# DA1470x register map
Vendor: Dialog; Series: DA1470x; File version: 1.2
CPU: CM33 r0p2, little endian, MPU, FPU, DSP, VTOR, 4 interrupt priority bits
Registers are 32-bit, read-write, reset 0x0 unless marked. A register's access mark holds for its fields unless they carry their own. Offsets are from the block's base; [hi:lo] are bit positions.

## CHARGER (part 1 of 2) — CHARGER registers
Base 0x51000600
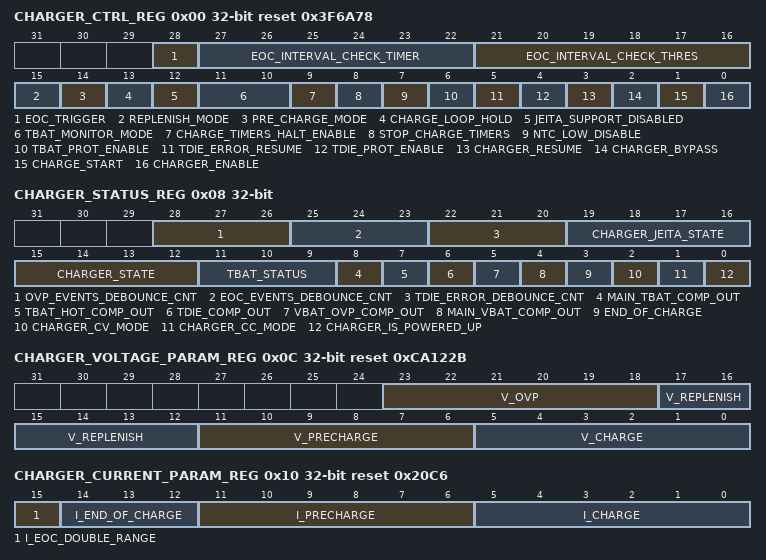
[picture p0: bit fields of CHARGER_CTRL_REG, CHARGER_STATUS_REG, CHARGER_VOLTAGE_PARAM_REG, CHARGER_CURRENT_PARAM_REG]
0x00 CHARGER_CTRL_REG reset 0x3F6A78 — Charger main control register
  [28] EOC_TRIGGER — 0 = Edge-sensitive End-of-Charge detection support is enabled (default). The Charger's digital block expects a positive edge of the End-of-Charge signal coming from the Charger's analog circuit to let the respective debounce counters start and enable the FSM switch to the END_OF_CHARGE state, if the signal is stable. 1 = Level-sensitive End-of-Charge detection is enabled. In this mode, the Charger's digital block only monitors the level of the End-of-Charge signal coming from the analog circuit and if this is seen high in either CC_CHARGE or CV_CHARGE state, the EOC debounce counters start.
  [27:22] EOC_INTERVAL_CHECK_TIMER ro — The specific bit-field determines the current state of the timer used to periodically check the End-of-Charge signal, as soon as the Charger's FSM is either in CC_CHARGE or CV_CHARGE state. Thus, as soon as the Charger's FSM enters the CC_CHARGE state: - The timer starts increasing when a positive edge detection on End-of-Charge signal occurs. - It keeps increasing until reaching the programmed EOC_INTERVAL_CHECK_THRES value, if and only if there is no detection of a negative edge on End-of-Charge signal. If this happens, the timer resets and starts over with a new End-of-Charge positive edge. - The timer also resets after having reached its programmed threshold or when the Charger's FSM next state is END_OF_CHARGE. This happens only after having found End-of-Charge signal asserted for 4 consecutive checks and provided that the specific signal has not de-asserted during the timer's interval. Note: It must be noted that out of these two states, the specific timer is kept to zero. It is also noted that this timer runs at the 1Mhz clock of the Charger's block and its value always ranges from 0 to the EOC_INTERVAL_CHECK_THRES value set in the respective bit-field of CHARGER_CTRL_REG.
  [21:16] EOC_INTERVAL_CHECK_THRES — This bit-field determines the periodic interval of checking the End-of-Charge signal, when the Charger's FSM is either in CC_CHARGE or in CV_CHARGE state. To implement this, a dedicated timer has been used, counting from zero up to the value programmed into this bit-field (see also EOC_INTERVAL_CHECK_TIMER field's description). As soon as this timer reaches the programmed value, the End-of-Charge signal is sampled and depending on its status (high or low), another counter, keeping the number of consecutive End-of-Charge events, is increased or not. See also the description of the EOC_DEBOUNCE_CNT bit-field of CHARGER_STATUS_REG, for this counter. Note: The specific bit-field should always be programmed to a non-zero value.
  [15] REPLENISH_MODE — When this bit-field is set and the Charger's FSM is in the BYPASSED state (thus, in Bypass mode), the internal multiplexer inside the digital part of the charger selects the Replenish, instead of the Pre-charge setting to be driven to the main Vbat comparator of the Charger's analogue circuitry. By this way, SW can read the respective analogue comparator's output in CHARGER_STATUS_REG (bit-field MAIN_VBAT_COMP_OUT), after the battery's volrtage has reached the End-of-Charge level, and determine if the battery voltage has dropped below the Replenish level, re-starting the battery charging accordingly. Note: When the Charger's FSM is active and operational, this bit-field is don't care and the FSM determines which level (Pre-charge or Replenish) will be selected and driven to the analogue, depending on the current state. It is also noted that the supported Pre-charge and Replenish levels can be viewed in the respective bit-fields defined in CHARGER_VOLTAGE_PARAM_REG register.
  [14] PRE_CHARGE_MODE — When set, this bit-field enables a signal of the same name with the bit-field, driven from the Charger's digital part towards the analogue circuitry, in order to determine the current in Pre-Charge mode. If the Charger's FSM is active and operational, the specific bit-field is don't care. Hence, it is considered only when the Charger's FSM has reached the BYPASSED state (thus, in Bypass mode). With the Charger's FSM being bypassed, SW should take over control and set the specific bit-field, in order to deliver the Pre-Charge instead of the normal Charge current to the Charger's analogue circuitry, during the Pre-Charge phase. Note: See also the description of CHARGER_CURRENT_PARAM_REG register for the Pre-Charge and normal Charge current levels supported.
  [13] CHARGE_LOOP_HOLD — When set, this bit-field disables charging, provided that the Charger's FSM has switched to the BYPASSED state. This is possible only by setting the CHARGER_BYPASS bit-field of this register. Thus, as soon as the Charger's FSM is bypassed, the respective signal driven by the FSM is overruled by this bit-field, making the analogue part of the Charger controllable also in this mode. If the Charger's FSM is not bypassed, this bit-field is don't care.
  [12] JEITA_SUPPORT_DISABLED — 0 = Charger's JEITA FSM monitoring the battery temperature checks also if battery temperature is in the Warm or Cool zones. In that case, it updates accordingly all the Charger's voltage levels (Charge, Pre-Charge, Replenish and OVP) programmed in CHARGER_VOLTAGE_PARAM_REG, as well as the charge and pre-charge current settings of CHARGER_CURRENT_PARAM_REG, depending on the temperature zone determined by the analogue circuitry of the Charger (see also the JEITA registers of the Charger's register file for the Voltage/Current levels in Warm and Cool temperature zones). 1 = Charger's JEITA FSM monitoring the battery temperature checks only if battery temperature is either in the Hot or Cold zones. In that case, it notifies the main Charger FSM to stop charging automatically, when in Hot zone. The same will happen also for the case of Cold, unless the NTC_LOW_DISABLE bit-field of CHARGER_CTRL_REG is set. Note : It is not recommended to have the specific bit-field kept to '0' (and thus the JEITA support enabled), if at the same time the bit-field TBAT_PROT_ENABLE of the same register is also '0'. Thus, JEITA support should be coupled with the Battery's temperature protection.
  [11:10] TBAT_MONITOR_MODE — Battery temperature pack monitoring modes, according to the following encoding: 00 = Battery temperature state checked and updated once, as soon as the charger is powered-up and settled. 01 = Battery temperature state checked periodically, depeding on TBAT_MON_TIMER_REG.TBAT_MON_INTERVAL and provided that Charger has been powered-up and charger's FSM is enabled. 10 = Battery temperature state checked periodically depending on TBAT_MON_TIMER_REG.TBAT_MON_INTERVAL, provided that Charger is powered-up and regardless if the Charger's FSM is enabled or not. Hence, this mode can be effective regardless of the state of CHARGE_START bit-field of CHARGER_CTRL_REG. 11 = When selected, it freezes the Battery temperature monitor FSM, as soon as the latter reaches the CHECK_IDLE state (see also CHARGER_STATUS_REG.CHARGER_JEITA_STATE bit-field's description for the states of this FSM). In this mode, the monitoring of Battery temperature is possible only by checking the status of TBAT_HOT_COMP_OUT and MAIN_TBAT_COMP_OUT bit-fields of CHARGER_STATUS_REG, thus by letting SW take over monitoring. This setting may be used in conjunction with Bypass mode (by setting CHARGER_BYPASS of CHARGER_CTRL_REG), so that both charging and battery temperature status monitoring are controlled by SW.
  [9] CHARGE_TIMERS_HALT_ENABLE — 0 = Charge timeout timers continue running when charging is disabled because of a Die or of a Battery temperature error, if and only if STOP_CHARGE_TIMERS bit-field is '0' (default). If it is '1', the counters are stopped also in TDIE_PROT and TBAT_PROT states. 1 = Charge timeout timers are halted in case of a Die or of a Battery temperature error. In that case, the global charge timer is stopped as soon as the Charger's FSM moves to TDIE_PROT or TBAT_PROT state. Also, either the Pre-Charge, the CC_CHARGE or the CV_CHARGE timer is also stopped, depending on the charging state of the FSM when the Die/Battery temperature error has been detected.
  [8] STOP_CHARGE_TIMERS — 0 = Charger's Pre-Charge, CC, CV and Total charge timeout timers are ticking properly, running at the 1Hz clock. 1 = All four Charger's timeout timers are halted, counting is disabled. The counters will be reset when the FSM is either in DISABLED or in END_OF_CHARGE state. Note: Value '0' is the recommended, '1' is a test mode, since it will globally halt the four timers and thus will block the generation of the respective timer expiration IRQs.
  [7] NTC_LOW_DISABLE — 0 = Charging is disabled when the battery temperature is found to have reached the "COLD" region. Therefore, the Charger's FSM moves directly to "TBAT_PROT" error and generates an IRQ to notify the system accordingly, in case the respective IRQ mask bit of CHARGER_ERROR_IRQ_MASK_REG is set. Also, CHARGER_ERROR_IRQ_STATUS_REG. TBAT_ERROR_IRQ field is updated accordingly. 1 = Charging is allowed to continue, even when the battery temperature pack reaches the "COLD" region. Consequently, the FSM continues charging and no battery temperature error event is generated.
  [6] TBAT_PROT_ENABLE — 0 = Battery temperature protection disabled 1 = Battery temperature protection enabled. Charging will be stopped in case Battery temperature reaches "Hot" zone. It will also be disabled when reaching "Cold" zone, provided that CHARGER_CTRL_REG.NTC_LOW_DISABLE is not set. This is handled by the Charger's FSM, which moves directly to the respective error state (TBAT_PROT), also generating an Error IRQ if the respective IRQ mask bit is set (see also CHARGER_ERROR_IRQ_MASK_REG).
  [5] TDIE_ERROR_RESUME — 0 = FSM will not resume from a Die temperature error. Consequently, its state will be staying to "TDIE_PROT", for as long as this bit-field is kept low, regardless of the status of the die tempeture comparator. Also, disabling the specific bit-field will reset the Die temperature error debounce counter, when the Charger's FSM is in TDIE_PROT state (so when a Die temperature error has been already detected) and the specific counter will remain frozen to 0 until the TDIE_ERROR_RESUME bit-field is set (see also the TDIE_ERROR_DEBOUNCE_CNT bit-field of CHARGER_STATUS_REG). 1 = FSM will resume from a Die temperature error, as soon as the respective analogue compator confirms that die temperature is again below the maximum allowed level. It is noted that the maximum Die temperature level is programmable via the CHARGER_TEMPSET_PARAM_REG register's respective bit-field (T_DIE_MAX).
  [4] TDIE_PROT_ENABLE — 0 = Die temperature protection is disabled, thus charging will not be disabled by the Charger's FSM in case of a Die temperature error. 1 = Die temperature protection is enabled, thus the Charger's FSM will move to "TDIE_PROT" state, disabling charging at the same time. It is noted that the Die temperature error event will be logged in the respective status bit of CHARGER_IRQ_ERROR_STATUS_REG and an IRQ will be generated, if and only if the corresponding mask bit of CHARGER_IRQ_MASK_REG is set.
  [3] CHARGER_RESUME — 0 = Charger's FSM is not enable to resume from a charge timeout error or a Vbat OVP (Over-Voltage Protection) error. Consequently, FSM stays in "ERROR" state. 1 = Charger's FSM will resume from a charge timeout or from an OVP error, thus its state will move from "ERROR" to "DISABLED" state, so that the charge cycle starts-over. It is noted that in the case of a Vbat OVP error, the FSM will leave "ERROR" state, as soon as the Vbat comparator for the OVP level shows that Vbat is again OK (so lower than the OVP setting).
  [2] CHARGER_BYPASS — 0 = Charger's FSM is active and running, notifying SW upon switching between its states 1 = Charger's FSM is bypassed, so its state stays to "BYPASS", so SW should take over the monitoring of the battery voltage and control of the charger.
  [1] CHARGE_START — 0 = Charger's FSM is disabled, FSM stays at "DISABLED" state 1 = Charger's FSM is enabled, so FSM's state can move from DISABLED to the actual charge states, starting from "PRE_CHARGE".
  [0] CHARGER_ENABLE — 0 = Charger's analogue circuitry is powered-down 1 = Charger's analogue circuitry is being powered-up and will be available after a certain settling time (in ms). As soon as this bit-field is set, the Charger's FSM waits for this settling time, before proceeding into DISABLED state, where it checks the Vbat level, as well as the Die temperature and the Battery temperature states. This is mandatory, before the actual charging begins, so before the FSM moves to PRE_CHARGE state. It is finally noted that the settling time is configurable via CHARGER_PWR_UP_TIMER_REG, counting with the 1Khz clock. Note: The Charger clocks must have been enabled first, by setting the CLK_SYS_REG[CLK_CHG_EN] bit-field to '1', in order to let the FSM proceed.
0x08 CHARGER_STATUS_REG — Charger main status register
  [28:26] OVP_EVENTS_DEBOUNCE_CNT ro — The specific bit-field returns the consecutive number of times Vbat has exceeded the programmed Over-Voltage Protection (OVP) level. It is used to determine when the Charger's FSM will exit any of the charging states (PRE/CC/CV_CHARGE) and will switch to the ERROR state due to an OVP error. This will happen as soon as the respective counter of OVP events reaches or exceeds a fixed number (4), similar to the approach adopted in the End-of-Charge and Die Temperature debouncing mechanisms. The specific counter increases only while the Charger's FSM is in any of the three charging,states, the Vbat OVP interval check timer has reached the threshold set and when Vbat OVP comparator's output is asserted. Note 1 : By default, as soon as the counter reaches 4, the FSM will switch to the ERROR state and the counter will reset again. Thus, in that case the specific counter ranges from 0 to 4 and vice-versa. However, if the monitoring of Vbat OVP comparator's state is less frequent than 5 (4+1) times the CHARGER_OVP_COMP_TIMER_REG[OVP_INTERVAL_CHECK_THRES] and Vbat has exceeded the OVP voltage level based on the comparator's output signal, then this counter will exceed 4 and may overflow. This will not harm, however, the detection of the OVP event, as it only increases the number of OVP event occurrences by the debounce timer, until the OVP comparator timer's settling time has expired. Thus, the Charger FSM will again switch to ERROR when the counter has reached or exceeded 4 (bit [2] of OVP_EVENTS_DEBOUNCE_CNT is set) and the OVP comparator's timer has expired. Note 2: See also the OVP_INTERVAL_CHECK_TIMER, OVP_INTERVAL_CHECK_THRES of CHARGER_OVP_COMP_TIMER_REG, for the debouncing mechanism of the Vbat OVP comparator's output.
  [25:23] EOC_EVENTS_DEBOUNCE_CNT ro — The specific bit-field returns the number of times the End-of-Charge signal has been consecutively found to be high. It is used to determine when the Charger's FSM will switch from CV_CHARGE to END_OF_CHARGE state, implementing a debounce mechanism on End-of-Charge signal, coming from the analogue circuitry of the Charger towards the FSM. The specific counter, running with the Charger's 1Mhz clock: - Increases after detecting that the End-of-Charge signal is high when the respective interval for the End-of-Charge check expires. This actually happens after having detected either a positive edge on the End-of-Charge signal or after having seen the signal's level to be high (see also CHARGER_CTRL_REG[EOC_TRIGGER]) , since only after that is it possible for the interval timer to start ticking. - Resets to zero when End-of-Charge is seen low when the interval timer has expired or when an End-of-Charge negative edge is seen before the timer's expiration, starting-over. - Does not count if End-of-Charge signal is seen high and either the CV_MODE signal (also driven by the analogue circutry) or the End-of-Charge signal of the previous clock cycle is seen low. - Is reset when the Charger's FSM is not in either the CC_CHARGE or the CV_CHARGE state or after having reached "100"(4). This is the threshold after which the End-of-Charge signal is considered stable by the Charger's FSM, to switch to the END_OF_CHARGE state. Thus, in practice, the specific counter (and bit-field) ranges between 0 and 4. Note: See also the EOC_INTERVAL_CHECK_TIMER/THRES bit-fields of CHARGER_CTRL_REG.
  [22:20] TDIE_ERROR_DEBOUNCE_CNT ro — The specific bit-field returns the consecutive number of times the Die temperature is seen either above (for the case of an error) or below (for the case of recovering from an error) the set Die temperature level.This is performed by a counter, which is increased: - Each time the Die temperature comparator shows that Die temperature exceeds the set level, and while charging is active, provided that Die temperature protection is enabled. If, however, the CHARGER_CTRL_REG.TDIE_PROT_ENABLE bit-field is not set, the counter is reset and stays frozen to zero. - Each time the Die temperature comparator shows that Die temperature is again below the set level, and while the FSM is in the Die temperature protection error state (TDIE_PROT) and the TDIE_ERROR_RESUME bit-field of CHARGER_CTRL_REG is set. If the specific bit-field is not set, the debounce counter is reset to 0 and it is kept frozen until the FSM is again enabled to resume from Die temperature errors. If the Die temperature comparator of the Charger's analogue circuitry shows that temperature has exceeded the programmed level for four consecutive times and charging is active, the Charger's FSM considers this as a Die temperature error and moves to the TDIE_PROT state, resetting the timer at the same time and of course halting charging. To recover from this state and resume charging, the FSM needs to see that Die temperature is below the programmed level for four consecutive times, again, provided that the TDIE_ERROR_RESUME bit-field of CHARGER_CTRL_REG is set. As soon as this happens, the error counter is again reset and the Charger's FSM resumes, by moving to PRE_CHARGE state. Consequently, the counter's value always ranges from 0 to 4. Note: When the Charger's FSM is in BYPASSED state, then this bit-field is reset and kept frozen to zero. Consequently, the number of times Die temperature has exceeded the pre-programmed threshold should be determined by SW.
  [19:16] CHARGER_JEITA_STATE ro — Returns the state of the Charger's JEITA FSM. This FSM is used to update the state of the battery temperature pack, depending on the value programmed in CHARGER_CTRL_REG.TBAT_MONITOR_MODE bit-field. The encoding of the states is as follows: 0x0 = CHECK_IDLE 0x1 = CHECK_THOT 0x2 = CHECK_TCOLD 0x3 = CHECK_TWARMER 0x4 = CHECK_TWARM 0x5 = CHECK_TCOOLER 0x6 = CHECK_TCOOL 0x7 = CHECK_TNORMAL 0x8 = UPDATE_TBAT The FSM initially is in CHECK_IDLE state and starts checking the battery's temperature by visiting the states that check for the respective temperature area (Hot, Cold, Warmer, Warm, Cooler, Cool, Normal), in this order. If the battery temperature is found to be in one of the aforementioned zones, it directly moves to UPDATE_TBAT state, to update the battery temperature's state and notify the main FSM of the Charger about the battery temperature status, before returning to the CHECK_IDLE state. A Charger State IRQ will also be generated upon refreshing the battery temperature status (see also the description of CHARGER_STATE_IRQ_MASK_REG register). Note: It is also noted that if the battery temperature is not found to be in any of the Hot, Cold, Warmer, Warm, Cooler or Cool zones, the FSM concludes that it is in the Normal zone, so between Warm and Cool. Consequently, the state CHECK_TNORMAL lasts only one (1MHz) clock cycle and is used to properly update the Battery temperature status (TBAT_STATUS) accordingly, before the last state (UPDATE_TBAT) is visited.
  [15:12] CHARGER_STATE ro — Indicating the state of the Charger's main FSM, based on the following encoding: 0x0 = POWER_UP (Charger's power-up not yet set) 0x1 = INIT (Charger is being power-up, FSM waiting for the analogue to settle) 0x2 = DISABLED (Charger powered-up but charging not yet started) 0x3 = PRE_CHARGE (Pre-Charge state) 0x4 = CC_CHARGE (Constant Current state) 0x5 = CV_CHARGE (Constant Voltage state) 0x6 = END_OF_CHARGE (End-of-Charge state) 0x7 = TDIE_PROT (Die temperature protection state, visited when Die temperature limit is exceeded) 0x8 = TBAT_PROT (Battery temperature protection state, visited when Battery temperature is either COLD or HOT) 0x9 = BYPASSED (Bypassed state, visited only when the FSM is bypassed and SW takes over control) 0xA = ERROR (Error state, visited when a charge time-out occurs or in the case of Vbat exceeding over-voltage level)
  [11:9] TBAT_STATUS ro — Battery pack temperature status, according to the following encoding: 0x0 : Battery temperature in COLD zone (default) 0x1 : Battery temperature in COOLER zone (above COLD) 0x2 : Battery temperature in COOL zone (above COOLER) 0x3 : Battery temperature in NORMAL zone (above COOL and below WARM zones) 0x4 : Battery temperature in WARM zone (above NORMAL) 0x5 : Battery temperature in WARMER zone (above WARM and below HOT) 0x6 : Battery temperature in HOT zone It is noted that, according to the JEITA standard (supported if the JEITA_SUPPORT_DISABLED bit-field of CHARGER_CTRL_REG is not set), if the battery pack temperature is in the "HOT" zone, charging will always be stopped. The same will happen also for the case of the COLD zone, unless the "NTC_LOW_DISABLE" bit-field of CHARGER_CTRL_REG is set. In that case, charging will be continued.
  [8] MAIN_TBAT_COMP_OUT ro — Returns the status of the main battery temperature comparator. This comparator by default checks if the battery temperature is in the Cold zone. However, if JEITA support is enabled and battery temperature is found to not be in either the Hot or the Cold zone, the same comparator is used to check for the Warm and Cool zones, as JEITA suggests. The specific bit-field is suggested to be used in bypass mode and when the JEITA support is disabled (so when the battery temperature is checked agains the Hot and the Cold zones). In that case, the comparator checks the battery temperature agains the Cold level and its status can be as follows: 0 = Battery temperature pack is found to be below the Cold level, so in the non-allowed Cold temperature zone. Thus, charging will be disabled, provided that the NTC_LOW_DISABLE bit-field of CHARGER_CTRL_REG is not set. 1 = Battery temperature pack is found to be above the non-allowed Cold temperature zone. Thus, charging will be continued, provided that battery temperature will not be in the Hot zone as well. When the Charger's main FSM is active and JEITA is enabled, the Charger's digital block takes over and controls the respective comparator's output.
  [7] TBAT_HOT_COMP_OUT ro — Returns the status of the battery temperature comparator dedicated to the Hot temperature zone. 0 = Battery temperature pack is found to be below the Hot zone 1 = Battery temperature pack is found to be in the non-allowed Hot temperature zone. Thus, charging will be disabled, provided that battery temperature protection is enabled.
  [6] TDIE_COMP_OUT ro — 0 = Die temperature is found to be below the programmed level, set in CHARGER_TEMPSET_PARAM_REG.TDIE_SET level (normal operation) 1 = Die temperature is found to be above the set level. Charging will be disabled if Die temperature protection is enabled and the Die temperature is found to be above the set level four consecutive times (see also TDIE_ERROR_DEBOUNCE_CNT bit-field). In that case, the Charger's FSM will also move the respective error state (TDIE_PROT) and an IRQ may be generated, if the respective mask bit of CHARGER_ERROR_IRQ_MASK_REG is set.
  [5] VBAT_OVP_COMP_OUT ro — 0 = Vbat has not exceeded the Over-Voltage Protection (OVP) voltage limit, according to the respective analogue comparator's output. 1 = Vbat is found to have exceeded the OVP voltage setting, thus charging should be disabled. The OVP voltage settings are defined in CHARGER_VOLTAGE_PARAM_REG.V_OVP (for the Normal battery temperature zone), as well as in CHARGER_JEITA_V_OVP_REG (for Cool and Warm temperature zones, to comply with JEITA).
  [4] MAIN_VBAT_COMP_OUT ro — This bit-field reflects the status of the main Vbat comparator residing in the analogue circuitry of the Charger. This comparator is used to check Vbat against either the Pre-Charge or the Replenish voltage level, depending on what is driven by the Charger's digital block. Thus, when the FSM is active, the comparator gets as reference the Replenish setting as soon as the FSM has reached the END_OF_CHARGE state. Otherwise,the Pre-Charge voltage setting is driven, including the Bypass mode. According to the above, the encoding is as follows for the case the comparator compares Vbat against the Pre-Charge level: 0 = Vbat has not exceeded the set Pre-Charge voltage level. 1 = Vbat has reached or exceeded the set Pre-Charge voltage level. For the case the comparator compares agains the Replenish level (when the FSM has reached the END_OF_CHARGE state, so when the charging has been completed), the encoding is as follows: 0 = Vbat has dropped below the set Replenish level, so charging will re-start and the FSM will move to the PRE_CHARGE state. 1 = Vbat is still greater or equal to the set Replenish level, thus charging remains in hold and the FSM in END_OF_CHARGE state.
  [3] END_OF_CHARGE ro — 0 = Actual charge current is above the current level programmed in I_END_OF_CHARGE field of CHARGER_CURRENT_PARAM_REG (or charger is off) 1 = Actual charge current is below the current level programmed in I_END_OF_CHARGE bit-field of CHARGER_CURRENT_PARAM_REG.
  [2] CHARGER_CV_MODE ro — 0 = Charger's voltage loop not in regulation (or Charger is off) 1 = Charger's Constant Voltage (CV) mode active, voltage loop in regulation
  [1] CHARGER_CC_MODE ro — 0 = Charger's Current loop not in regulation (or Charger is off) 1 = Charger's Constant Current (CC) mode active, current loop in regulation
  [0] CHARGER_IS_POWERED_UP ro — 0 = Charger is either off or it is being powered-on but the analogue ciruitry is not yet settled. The charger's main FSM is either in POWER_UP or INIT states. 1 = Charger is powered-up, so its analogue ciruitry should now be settled. The Charger's FSM has left both power-up states (POWER_UP, INIT), so charging can start.
0x0C CHARGER_VOLTAGE_PARAM_REG reset 0xCA122B — Charger voltage settings register
  [23:18] V_OVP — This bit-field determines the VBAT Over-voltage protection limit. This Over-voltage protection level is used by the Charger's analogue circuitry and specifically by a dedicated comparator, the output of which is sampled by the digital block of the Charger. As soon as VBAT is detected to have reached or exceeded this level, the Charger's FSM moves to ERROR state, interrupting charging. If the respective Error IRQ mask bit is set, an Error IRQ pulse will be also generated. Regarding the actual range of supported values for this bit-field, see the the description of V_CHARGE bit-field of this register.
  [17:12] V_REPLENISH — This bit-field determines the absolute value (in V) of the Replenish voltage threshold. As soon as charging has been completed and the Charger's FSM has reached the END_OF_CHARGE state, the respective analogue comparator of the Charger compares VBAT with the Replenish level. If VBAT is found to have dropped below this level, charging should start-over again and in that case, the FSM moves again to the PRE_CHARGE state. Regarding the supported Replenish voltage levels, see the description of V_CHARGE bit-field.
  [11:6] V_PRECHARGE — This bit-field determines the voltage level at which the battery is considered as Pre-charged and therefore the Charger's FSM should move to the CC_CHARGE state, entering the Constant Current charging phase. Regarding the supported Pre-Charge voltage levels, see also the description of V_CHARGE bit-field of this register.
  [5:0] V_CHARGE — This bit-field determines the charge voltage levels supported. The supported levels are determined according to the following encoding: 0 : 2.80V 1 : 2.85V 2 : 2.90V 3 : 2.95V 4 : 3.00V 5 : 3.05V 6 : 3.10V 7 : 3.15V 8 : 3.20V 9 : 3.25V 10 : 3.30V 11 : 3.35V 12 : 3.40V 13 : 3.45V 14 : 3.50V 15 : 3.55V 16 : 3.60V 17 : 3.65V 18 : 3.70V 19 : 3.75V 20 : 3.80V 21 : 3.82V 22 : 3.84V 23 : 3.86V 24 : 3.88V 25 : 3.90V 26 : 3.92V 27 : 3.94V 28 : 3.96V 29 : 3.98V 30 : 4.00V 31 : 4.02V 32 : 4.04V 33 : 4.06V 34 : 4.08V 35 : 4.10V 36 : 4.12V 37 : 4.14V 38 : 4.16V 39 : 4.18V 40 : 4.20V 41 : 4.22V 42 : 4.24V 43 : 4.26V 44 : 4.28V 45 : 4.30V 46 : 4.32V 47 : 4.34V 48 : 4.36V 49 : 4.38V 50 : 4.40V 51 : 4.42V 52 : 4.44V 53 : 4.46V 54 : 4.48V 55 : 4.50V 56 : 4.52V 57 : 4.54V 58 : 4.56V 59 : 4.58V 60 : 4.60V 61 : 4.70V 62 : 4.80V 63 : 4.90V* It has to be noted that the specific values correspond to the normal battery temperature zone. However, the specific register field may be updated by the JEITA FSM (which checks the battery temperature either once or periodically), in order to adapt the charge voltage to the battery temperature zone (see also CHARGER_CTRL_REG.TBAT_MONITOR_MODE field as well). This is valid also for the other three fields of the current register. Consequently, in that case the register returns the Charge voltage settings that abide to the JEITA requirements for the battery (either COOL, WARM or NORMAL). Note: Option "63" (4.90V) is not supported for V_CHARGE, V_PRECHARGE and V_REPLENISH bit-fields (and respective levels). It should be used only in the V_OVP bit-field, as the (maximum) Over-voltage protection level.
0x10 CHARGER_CURRENT_PARAM_REG reset 0x20C6 — Charger current settings register
  [15] I_EOC_DOUBLE_RANGE — When set, the specific bit-field enables an increase of the (%) range of End-of-Charge current setting. Consequently, the default lower and upper limits of 6% of I_CHARGE (value 0x0 of I_END_OF_CHARGE bit-field) and 20% (value 0x7 of the same bit-field) are increased to 12% and 40% respectively, as soon as the I_EOC_DOUBLE_RANGE bit-field is set.
  [14:12] I_END_OF_CHARGE — End-of-Charge current setting, ranging from 6%("000") to 20% ("111") of the charge current setting, with a step size of 2%, as follows (when I_EOC_DOUBLE_RANGE = 0): 000 : 6% 001 : 8% 010 : 10% 011 : 12% 100 : 14% 101 : 16% 110 : 18% 111 : 20% When I_EOC_DOUBLE_RANGE = 1, the range is: 000 : 12% 001 : 16% 010 : 20% 011 : 24% 100 : 28% 101 : 32% 110 : 36% 111 : 40%
  [11:6] I_PRECHARGE — This bit-field determines the Pre-Charge current, in mA, ranging from 0.5 to 72mA, according to the following encoding: 0 : 0.5 mA 1 : 1 mA 2 : 1.5mA 3 : 2 mA 4 : 2.5mA 5 : 3 mA 6 : 3.5mA 7 : 4 mA 8 : 4.5mA 9 : 5 mA 10 : 5.5mA 11 : 6 mA 12 : 6.5mA 13 : 7 mA 14 : 7.5mA 15 : 8 mA 16 : 9 mA 17 : 10 mA 18 : 11 mA 19 : 12 mA 20 : 13 mA 21 : 14 mA 22 : 15 mA 23 : 16 mA 24 : 17 mA 25 : 18 mA 26 : 19 mA 27 : 20 mA 28 : 21 mA 29 : 22 mA 30 : 23 mA 31 : 24 mA 32 : 27 mA 33 : 30 mA 34 : 33 mA 35 : 36 mA 36 : 39 mA 37 : 42 mA 38 : 45 mA 39 : 48 mA 40 : 51 mA 41 : 54 mA 42 : 57 mA 43 : 60 mA 44 : 63 mA 45 : 66 mA 46 : 69 mA 47 : 72 mA 48 : 72 mA 49 : 72 mA 50 : 72 mA 51 : 72 mA 52 : 72 mA 53 : 72 mA 54 : 72 mA 55 : 72 mA 56 : 72 mA 57 : 72 mA 58 : 72 mA 59 : 72 mA 60 : 72 mA 61 : 72 mA 62 : 72 mA 63 : 72 mA
  [5:0] I_CHARGE — This bit-field determines the charge current range, in mA. The range is from 5mA to 720mA, according to the following encoding: 0 : 5 mA 1 : 10 mA 2 : 15 mA 3 : 20 mA 4 : 25 mA 5 : 30 mA 6 : 35 mA 7 : 40 mA 8 : 45 mA 9 : 50 mA 10 : 55 mA 11 : 60 mA 12 : 65 mA 13 : 70 mA 14 : 75 mA 15 : 80 mA 16 : 90 mA 17 : 100 mA 18 : 110 mA 19 : 120 mA 20 : 130 mA 21 : 140 mA 22 : 150 mA 23 : 160 mA 24 : 170 mA 25 : 180 mA 26 : 190 mA 27 : 200 mA 28 : 210 mA 29 : 220 mA 30 : 230 mA 31 : 240 mA 32 : 270 mA 33 : 300 mA 34 : 330 mA 35 : 360 mA 36 : 390 mA 37 : 420 mA 38 : 450 mA 39 : 480 mA 40 : 510 mA 41 : 540 mA 42 : 570 mA 43 : 600 mA 44 : 630 mA 45 : 660 mA 46 : 690 mA 47 : 720 mA 48 : 720 mA 49 : 720 mA 50 : 720 mA 51 : 720 mA 52 : 720 mA 53 : 720 mA 54 : 720 mA 55 : 720 mA 56 : 720 mA 57 : 720 mA 58 : 720 mA 59 : 720 mA 60 : 720 mA 61 : 720 mA 62 : 720 mA 63 : 720 mA Note: It has to be noted that the specific values correspond to the normal battery temperature zone. However, the specific register field may be updated by the JEITA FSM (which checks the battery temperature either once or periodically), in order to adapt the Charge current to the new battery temperature zone (see also CHARGER_CTRL_REG.TBAT_MONITOR_MODE field as well). This is valid also for the Pre-Charge current field of this register and provided that JEITA support is enabled in CHARGER_CTRL_REG. Consequently, in that case the register return the Charge current settings that abide to the JEITA requirements for the battery (either COOLER, COOL, WARM or NORMAL).
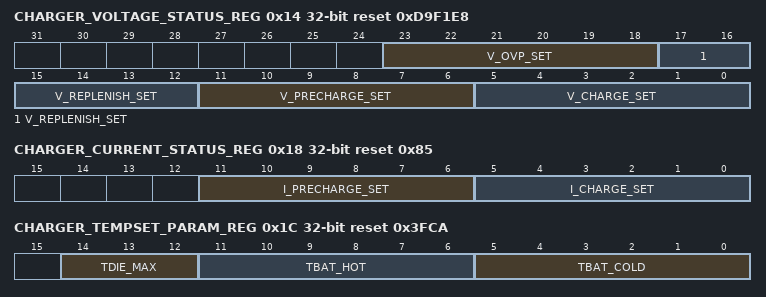
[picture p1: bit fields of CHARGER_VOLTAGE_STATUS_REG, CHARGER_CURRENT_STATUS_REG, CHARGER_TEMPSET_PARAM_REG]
0x14 CHARGER_VOLTAGE_STATUS_REG reset 0xD9F1E8 — Charger voltage status register
  [23:18] V_OVP_SET ro — This bit-field returns the applied V_OVP setting. In JEITA charging, it contains the value corresponding to the present battery temperature zone, according to JEITA_V_OVP_REG. If JEITA charging is disabled, it reflects the V_OVP bit-field of CHARGER_VOLTAGE_PARAM_REG. The specific bit-field is updated by the battery monitoring (JEITA) FSM, as soon as the latter starts running. Until then, it reflects the corresponding bit-field of CHARGER_VOLTAGE_PARAM_REG.
  [17:12] V_REPLENISH_SET ro — This bit-field returns the applied V_REPLENISH setting. In JEITA charging, it contains the value corresponding to the present battery temperature zone, according to JEITA_V_REPLENISH_REG. If JEITA charging is disabled, it reflects the V_REPLENISH bit-field of CHARGER_VOLTAGE_PARAM_REG. The specific bit-field is updated by the battery monitoring (JEITA) FSM, as soon as the latter starts running. Until then, it reflects the corresponding bit-field of CHARGER_VOLTAGE_PARAM_REG.
  [11:6] V_PRECHARGE_SET ro — This bit-field returns the applied V_PRECHARGE setting. In JEITA charging, it contains the value corresponding to the present battery temperature zone, according to JEITA_V_PRECHARGE_REG. If JEITA charging is disabled, it reflects the V_PRECHARGE bit-field of CHARGER_VOLTAGE_PARAM_REG. The specific bit-field is updated by the battery monitoring (JEITA) FSM, as soon as the latter starts running. Until then, it reflects the corresponding bit-field of CHARGER_VOLTAGE_PARAM_REG.
  [5:0] V_CHARGE_SET ro — This bit-field returns the applied V_CHARGE setting. In JEITA charging, it contains the value corresponding to the present battery temperature zone, according to JEITA_V_CHARGE_REG. If JEITA charging is disabled, it reflects the V_CHARGE bit-field of CHARGER_VOLTAGE_PARAM_REG. The specific bit-field is updated by the battery monitoring (JEITA) FSM, as soon as the latter starts running. Until then, it reflects corresponding the bit-field of CHARGER_VOLTAGE_PARAM_REG.
0x18 CHARGER_CURRENT_STATUS_REG reset 0x85 — Charger current status register
  [11:6] I_PRECHARGE_SET ro — This bit-field returns the applied Pre-Charge current setting. In JEITA charging, it contains the Pre-Charge value corresponding to the present battery temperature zone, according to JEITA_CURRENT/CURRENT2_SETTINGS_REG. If JEITA charging is disabled, it reflects the value of I_PRECHARGE bit-field CHARGER_CURRENT_PARAM_REG. The specific bit-field is updated by the battery monitoring (JEITA) FSM, as soon as the latter starts running. Until then, it reflects the corresponding bit-field of CHARGER_CURRENT_PARAM_REG.
  [5:0] I_CHARGE_SET ro — This bit-field returns the applied CC current setting. In JEITA charging, it contains the value corresponding to the present battery temperature zone, according to CHARGER_JEITA_CURRENT/CURRENT2_REG. If JEITA charging is disabled, it reflects the value of I_CHARGE bit-field CHARGER_CURRENT_PARAM_REG. The specific bit-field is updated by the battery monitoring (JEITA) FSM, as soon as the latter starts running. Until then, it reflects the corresponding bit-field of CHARGER_CURRENT_PARAM_REG.
0x1C CHARGER_TEMPSET_PARAM_REG reset 0x3FCA — Charger battery temperature settings register
  [14:12] TDIE_MAX — This bit-field determines the maximum Die temperature level limit, ranging from 0C to 130C, according to the following encoding: 000: 0 C (mainly for test purposes) 001: 50 C 010: 80 C 011: 90 C 100: 100 C 101: 110 C 110: 120 C 111: 130 C
  [11:6] TBAT_HOT — This bit-field determines the battery temperature above which the charge current is zero, defining the "Hot" battery temperature zone. It ranges from minus 10C to 53C. The range is the same with the one defined in detail in TBAT_COLD bit-field.
  [5:0] TBAT_COLD — This bit-field determines the battery temperature below which the charge current is zero, defining the "Cold" temperature zone. The range of covered temperatures is provided in the following list, which also includes the "Comparator Ladder Reference" ratio (defined in Section 3.11.2.3 of "Lithium_Dialog_Design_Documentation" document). 0 : -10C/0.741 1 : -9C/0.733 2 : -8C/0.724 3 : -7C/0.715 4 : -6C/0.706 5 : -5C/0.695 6 : -4C/0.686 7 : -3C/0.677 8 : -2C/0.668 9 : -1C/0.657 10 : 0C/0.647 11 : 1C/0.638 12 : 2C/0.628 13 : 3C/0.618 14 : 4C/0.608 15 : 5C/0.596 16 : 6C/0.587 17 : 7C/0.578 18 : 8C/0.567 19 : 9C/0.557 20 : 10C/0.546 21 : 11C/0.536 22 : 12C/0.527 23 : 13C/0.517 24 : 14C/0.506 25 : 15C/0.495 26 : 16C/0.486 27 : 17C/0.477 28 : 18C/0.467 29 : 19C/0.457 30 : 20C/0.446 31 : 21C/0.438 32 : 22C/0.429 33 : 23C/0.419 34 : 24C/0.410 35 : 25C/0.400 36 : 26C/0.392 37 : 27C/0.383 38 : 28C/0.375 39 : 29C/0.366 40 : 30C/0.356 41 : 31C/0.349 42 : 32C/0.341 43 : 33C/0.333 44 : 34C/0.325 45 : 35C/0.316 46 : 36C/0.309 47 : 37C/0.302 48 : 38C/0.295 49 : 39C/0.287 50 : 40C/0.280 51 : 41C/0.273 52 : 42C/0.267 53 : 43C/0.260 54 : 44C/0.253 55 : 45C/0.247 56 : 46C/0.241 57 : 47C/0.235 58 : 48C/0.229 59 : 49C/0.223 60 : 50C/0.217 61 : 51C/0.212 62 : 52C/0.207 63 : 53C/0.202
